# AC7802x register map
Vendor: AutoChips; Series: AC78; File version: 1.0
CPU: CM0PLUS r0p1, little endian, no MPU, no FPU, VTOR, 2 interrupt priority bits
Registers are 32-bit, read-write, reset 0x0 unless marked. A register's access mark holds for its fields unless they carry their own. Offsets are from the block's base; [hi:lo] are bit positions; {n}, {i} and the like mark numbered series.

## SPM — System Power Manage
Base 0x40008000
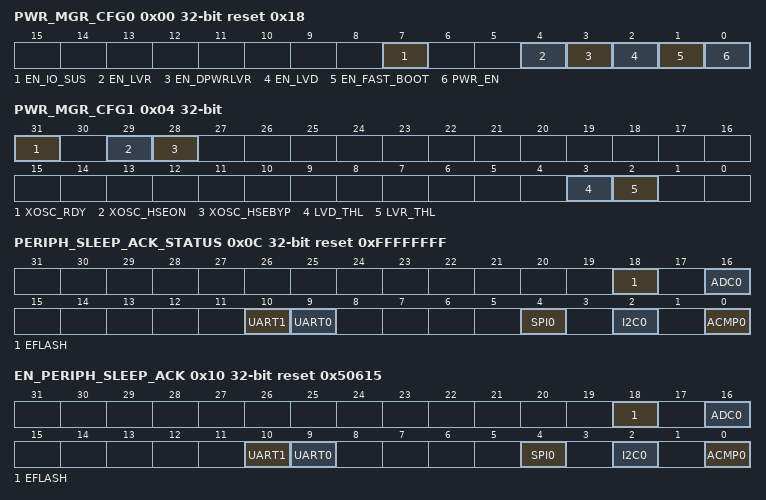
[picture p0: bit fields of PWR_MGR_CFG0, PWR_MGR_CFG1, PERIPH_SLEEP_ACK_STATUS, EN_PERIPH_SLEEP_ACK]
0x00 PWR_MGR_CFG0 reset 0x18 — Power Manage Config Register 0
  [7] EN_IO_SUS — Enable IO Suspend In Stop Mode
    0=IO Keep Status; 1=IO Change To Suspend
  [4] EN_LVR — Enable Low Voltage Reset Function
    0=Disable; 1=Enable
  [3] EN_DPWRLVR — Enable Digital Low Voltage Reset
    0=Disable; 1=Enable
  [2] EN_LVD — Enable Low Voltage Detect
    0=Disable; 1=Enable
  [1] EN_FAST_BOOT — Enable Fast Boot Mode
    0=Dsable; 1=Enable
  [0] PWR_EN — SPM Power Control Enable
    0=Disable; 1=Enable
0x04 PWR_MGR_CFG1 — Power Manage Config Register 1
  [31] XOSC_RDY ro — XOSC Clock Ready Flag
    0=Not Ready; 1=Ready
  [29] XOSC_HSEON — Extern High-Speed Clock Enable
    0=Disable XOSC HSE; 1=Enable XOSC HSE
  [28] XOSC_HSEBYP — Extern High-Speed Clock Bypass
    0=Disable XOSC HSE Bypass; 1=Enable XOSC HSE Bypass
  [3] LVD_THL — LVD Threshold Voltage
    0=Low Threshold; 1=High Threshold
  [2] LVR_THL — LVR Threshold Voltage
    0=Low Threshold; 1=High Threshold
0x0C PERIPH_SLEEP_ACK_STATUS ro reset 0xFFFFFFFF
  [18] EFLASH — Flash Idle Status
    0=Busy; 1=Idle
  [16] ADC0 — ADC0 Sleep ACK Status
    0=No ACK; 1=ACK
  [10] UART1 — UART1 Sleep ACK Status
    0=No ACK; 1=ACK
  [9] UART0 — UART0 Sleep ACK Status
    0=No ACK; 1=ACK
  [4] SPI0 — SPI0 Sleep ACK Status
    0=No ACK; 1=ACK
  [2] I2C0 — I2C0 Sleep ACK Status
    0=No ACK; 1=ACK
  [0] ACMP0 — ACMP0 Sleep ACK Status
    0=No ACK; 1=ACK
0x10 EN_PERIPH_SLEEP_ACK reset 0x50615 — Enable Periph Sleep Ack
  [all] fields
    0=Disable; 1=Enable
  [18] EFLASH — Enable Flash Sleep Ack
  [16] ADC0 — Enable ADC0 Sleep Ack
  [10] UART1 — Enable UART1 Sleep Ack
  [9] UART0 — Enable UART0 Sleep Ack
  [4] SPI0 — Enable SPI0 Sleep Ack
  [2] I2C0 — Enable I2C0 Sleep Ack
  [0] ACMP0 — Enable ACMP0 Sleep Ack
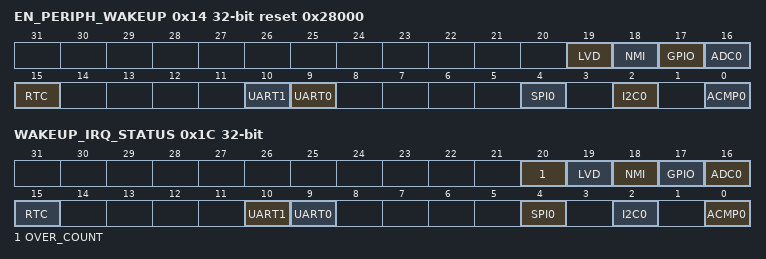
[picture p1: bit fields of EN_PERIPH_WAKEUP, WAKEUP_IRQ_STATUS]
0x14 EN_PERIPH_WAKEUP reset 0x28000 — Enable Periph Wakeup
  [all] fields
    0=Disable; 1=Enable
  [19] LVD — Enable LVD Wakeup
  [18] NMI — Enable NMI Wakeup
  [17] GPIO — Enable GPIO Wakeup
  [16] ADC0 — Enable ADC0 Wakeup
  [15] RTC — Enable RTC Wakeup
  [10] UART1 — Enable UART1 Wakeup
  [9] UART0 — Enable UART0 Wakeup
  [4] SPI0 — Enable SPI0 Wakeup
  [2] I2C0 — Enable I2C0 Wakeup
  [0] ACMP0 — Enable ACMP0 Wakeup
0x1C WAKEUP_IRQ_STATUS — SPM Wakeup IRQ Status
  [all] fields
    0=Invalid; 1=Valid
  [20] OVER_COUNT — SPM Overcount Wakeup Flag
  [19] LVD — LVD Wakeup Flag
  [18] NMI — NMI Wakeup Flag
  [17] GPIO — GPIO Wakeup Flag
  [16] ADC0 — ADC0 Wakeup Flag
  [15] RTC — RTC Wakeup Flag
  [10] UART1 — UART1 Wakeup Flag
  [9] UART0 — UART0 Wakeup Flag
  [4] SPI0 — SPI0 Wakeup Flag
  [2] I2C0 — I2C0 Wakeup Flag
  [0] ACMP0 — ACMP0 Wakeup Flag

## GPIOA — General Purpose Input/Output
Base 0x20080000
Same registers: GPIOB 0x20080030
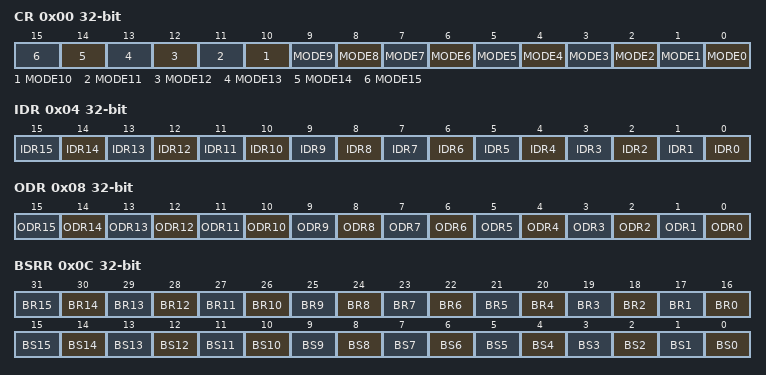
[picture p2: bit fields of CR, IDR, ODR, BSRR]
0x00 CR — GPIO Configuration Register
  [n] MODE{n} (n=0..15) — MODE{n}[0] bits (Port mode bits, pin {n})
0x04 IDR ro — GPIO Input Data Register
  [n] IDR{n} (n=0..15) — Port input data, bit {n}
0x08 ODR — GPIO Output Data Register
  [n] ODR{n} (n=0..15) — Port output data, bit {n}
0x0C BSRR — GPIO Bit Set, Reset Register
  [n+16] BR{n} (n=0..15) — Port Reset bit {n}
  [n] BS{n} (n=0..15) — Port Set bit {n}
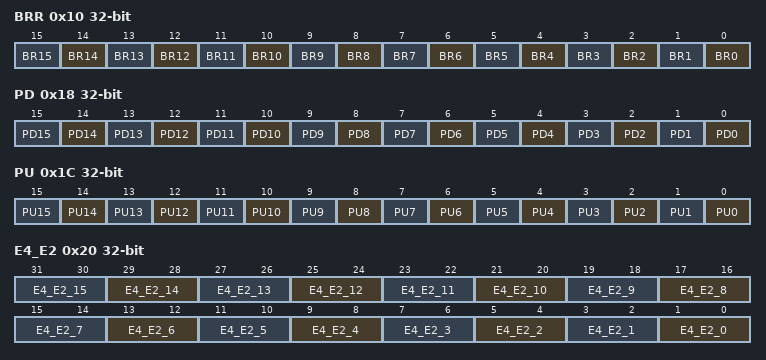
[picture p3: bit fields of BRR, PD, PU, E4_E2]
0x10 BRR — GPIO Bit Reset Register
  [n] BR{n} (n=0..15) — Port Reset bit {n}
0x18 PD — GPIO Pull Down Register
  [n] PD{n} (n=0..15) — Port Pin {n} pull down
0x1C PU — GPIO Pull Up Register
  [n] PU{n} (n=0..15) — Port Pin {n} pull up
0x20 E4_E2 — GPIO E4_E2 Register
  [all] fields
    0=4mA (Driving 4mA); 1=8mA (Driving 8mA); 2=12mA (Driving 12mA); 3=16mA (Driving 16mA)
  [2n+1:2n] E4_E2_{n} (n=0..15) — Port Pin {n} driving current
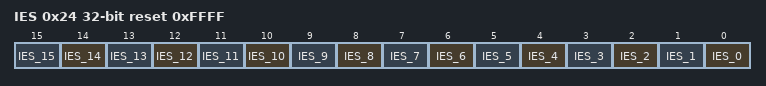
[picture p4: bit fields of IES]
0x24 IES reset 0xFFFF — GPIO IES Register
  [all] fields
    0=Disable (Input disable); 1=Enable (Input enable)
  [n] IES_{n} (n=0..15) — Port Pin {n} input enable
